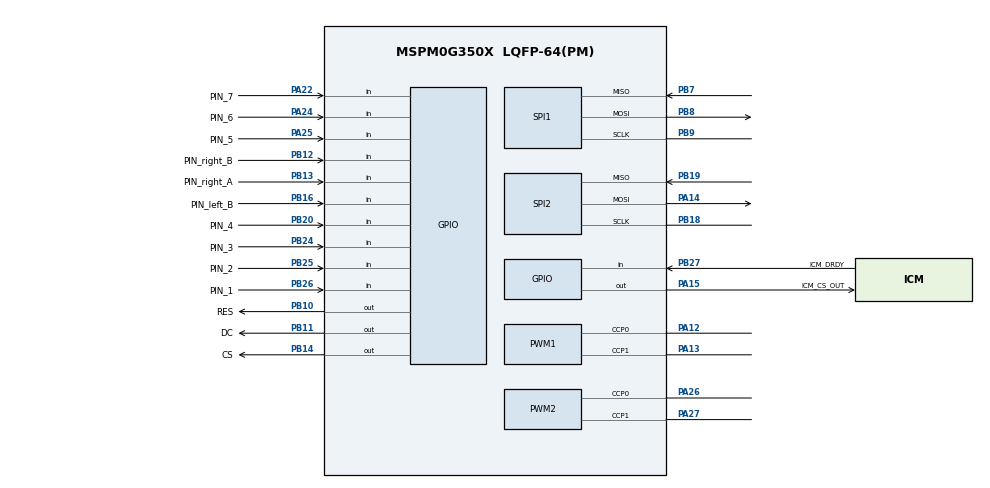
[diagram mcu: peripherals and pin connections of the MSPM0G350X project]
/**
 * @cliArgs --device "MSPM0G350X" --part "Default" --package "LQFP-64(PM)" --product "mspm0_sdk@2.10.00.04"
 * @versions {"tool":"1.26.2+4477"}
 */

/**
 * Import the modules used in this configuration.
 */
const GPIO   = scripting.addModule("/ti/driverlib/GPIO", {}, false);
const GPIO1  = GPIO.addInstance();
const GPIO2  = GPIO.addInstance();
const GPIO3  = GPIO.addInstance();
const GPIO4  = GPIO.addInstance();
const GPIO5  = GPIO.addInstance();
const PWM    = scripting.addModule("/ti/driverlib/PWM", {}, false);
const PWM1   = PWM.addInstance();
const PWM2   = PWM.addInstance();
const SPI    = scripting.addModule("/ti/driverlib/SPI", {}, false);
const SPI1   = SPI.addInstance();
const SPI2   = SPI.addInstance();
const SYSCTL = scripting.addModule("/ti/driverlib/SYSCTL");
const TIMER  = scripting.addModule("/ti/driverlib/TIMER", {}, false);
const TIMER1 = TIMER.addInstance();

/**
 * Write custom configuration values to the imported modules.
 */
const divider9       = system.clockTree["UDIV"];
divider9.divideValue = 2;

const mux4       = system.clockTree["EXHFMUX"];
mux4.inputSelect = "EXHFMUX_XTAL";

const mux8       = system.clockTree["HSCLKMUX"];
mux8.inputSelect = "HSCLKMUX_SYSPLL2X";

const mux12       = system.clockTree["SYSPLLMUX"];
mux12.inputSelect = "zSYSPLLMUX_HFCLK";

const pinFunction4       = system.clockTree["HFXT"];
pinFunction4.enable      = true;
pinFunction4.inputFreq   = 40;
pinFunction4.HFXTStartup = 10;

GPIO1.$name                         = "OLED";
GPIO1.port                          = "PORTB";
GPIO1.associatedPins.create(3);
GPIO1.associatedPins[0].$name       = "RES";
GPIO1.associatedPins[0].ioStructure = "SD";
GPIO1.associatedPins[0].assignedPin = "10";
GPIO1.associatedPins[0].pin.$assign = "PB10";
GPIO1.associatedPins[1].$name       = "DC";
GPIO1.associatedPins[1].ioStructure = "SD";
GPIO1.associatedPins[1].assignedPin = "11";
GPIO1.associatedPins[1].pin.$assign = "PB11";
GPIO1.associatedPins[2].$name       = "CS";
GPIO1.associatedPins[2].ioStructure = "SD";
GPIO1.associatedPins[2].assignedPin = "14";
GPIO1.associatedPins[2].pin.$assign = "PB14";

const Board = scripting.addModule("/ti/driverlib/Board", {}, false);

GPIO2.$name                          = "ICM_CS";
GPIO2.associatedPins[0].$name        = "ICM_CS_OUT";
GPIO2.associatedPins[0].assignedPort = "PORTA";
GPIO2.associatedPins[0].assignedPin  = "15";
GPIO2.associatedPins[0].pin.$assign  = "PA15";

GPIO3.$name                          = "ICM_INT";
GPIO3.associatedPins[0].$name        = "ICM_DRDY";
GPIO3.associatedPins[0].assignedPort = "PORTB";
GPIO3.associatedPins[0].assignedPin  = "27";
GPIO3.associatedPins[0].direction    = "INPUT";
GPIO3.associatedPins[0].interruptEn  = true;
GPIO3.associatedPins[0].polarity     = "RISE";
GPIO3.associatedPins[0].pin.$assign  = "PB27";

GPIO4.$name                              = "GPIO_Encoder";
GPIO4.associatedPins.create(4);
GPIO4.associatedPins[0].$name            = "PIN_right_A";
GPIO4.associatedPins[0].direction        = "INPUT";
GPIO4.associatedPins[0].interruptEn      = true;
GPIO4.associatedPins[0].polarity         = "RISE";
GPIO4.associatedPins[0].internalResistor = "PULL_UP";
GPIO4.associatedPins[0].pin.$assign      = "PB13";
GPIO4.associatedPins[1].$name            = "PIN_right_B";
GPIO4.associatedPins[1].direction        = "INPUT";
GPIO4.associatedPins[1].internalResistor = "PULL_UP";
GPIO4.associatedPins[1].interruptEn      = true;
GPIO4.associatedPins[1].polarity         = "RISE";
GPIO4.associatedPins[1].pin.$assign      = "PB12";
GPIO4.associatedPins[2].direction        = "INPUT";
GPIO4.associatedPins[2].internalResistor = "PULL_UP";
GPIO4.associatedPins[2].interruptEn      = true;
GPIO4.associatedPins[2].polarity         = "RISE";
GPIO4.associatedPins[2].$name            = "PIN_left_A";
GPIO4.associatedPins[3].$name            = "PIN_left_B";
GPIO4.associatedPins[3].direction        = "INPUT";
GPIO4.associatedPins[3].interruptEn      = true;
GPIO4.associatedPins[3].polarity         = "RISE";
GPIO4.associatedPins[3].internalResistor = "PULL_UP";
GPIO4.associatedPins[3].pin.$assign      = "PB16";

GPIO5.$name                              = "GPIO_xunji";
GPIO5.associatedPins.create(7);
GPIO5.associatedPins[0].$name            = "PIN_1";
GPIO5.associatedPins[0].direction        = "INPUT";
GPIO5.associatedPins[0].internalResistor = "PULL_DOWN";
GPIO5.associatedPins[0].pin.$assign      = "PB26";
GPIO5.associatedPins[1].$name            = "PIN_2";
GPIO5.associatedPins[1].direction        = "INPUT";
GPIO5.associatedPins[1].internalResistor = "PULL_DOWN";
GPIO5.associatedPins[1].pin.$assign      = "PB25";
GPIO5.associatedPins[2].$name            = "PIN_3";
GPIO5.associatedPins[2].direction        = "INPUT";
GPIO5.associatedPins[2].internalResistor = "PULL_DOWN";
GPIO5.associatedPins[2].pin.$assign      = "PB24";
GPIO5.associatedPins[3].$name            = "PIN_4";
GPIO5.associatedPins[3].direction        = "INPUT";
GPIO5.associatedPins[3].internalResistor = "PULL_DOWN";
GPIO5.associatedPins[3].pin.$assign      = "PB20";
GPIO5.associatedPins[4].$name            = "PIN_5";
GPIO5.associatedPins[4].direction        = "INPUT";
GPIO5.associatedPins[4].internalResistor = "PULL_DOWN";
GPIO5.associatedPins[4].pin.$assign      = "PA25";
GPIO5.associatedPins[5].$name            = "PIN_6";
GPIO5.associatedPins[5].direction        = "INPUT";
GPIO5.associatedPins[5].internalResistor = "PULL_DOWN";
GPIO5.associatedPins[5].pin.$assign      = "PA24";
GPIO5.associatedPins[6].$name            = "PIN_7";
GPIO5.associatedPins[6].direction        = "INPUT";
GPIO5.associatedPins[6].internalResistor = "PULL_DOWN";
GPIO5.associatedPins[6].pin.$assign      = "PA22";

PWM1.$name                              = "PWM_left";
PWM1.timerStartTimer                    = true;
PWM1.peripheral.ccp0Pin.$assign         = "PA12";
PWM1.peripheral.ccp1Pin.$assign         = "PA13";
PWM1.PWM_CHANNEL_0.$name                = "ti_driverlib_pwm_PWMTimerCC0";
PWM1.PWM_CHANNEL_1.$name                = "ti_driverlib_pwm_PWMTimerCC1";
PWM1.ccp0PinConfig.$name                = "ti_driverlib_gpio_GPIOPinGeneric0";
PWM1.ccp0PinConfig.direction            = scripting.forceWrite("OUTPUT");
PWM1.ccp0PinConfig.hideOutputInversion  = scripting.forceWrite(false);
PWM1.ccp0PinConfig.onlyInternalResistor = scripting.forceWrite(false);
PWM1.ccp0PinConfig.passedPeripheralType = scripting.forceWrite("Digital");
PWM1.ccp1PinConfig.$name                = "ti_driverlib_gpio_GPIOPinGeneric1";
PWM1.ccp1PinConfig.direction            = scripting.forceWrite("OUTPUT");
PWM1.ccp1PinConfig.hideOutputInversion  = scripting.forceWrite(false);
PWM1.ccp1PinConfig.onlyInternalResistor = scripting.forceWrite(false);
PWM1.ccp1PinConfig.passedPeripheralType = scripting.forceWrite("Digital");

PWM2.$name                              = "PWM_right";
PWM2.timerStartTimer                    = true;
PWM2.clockDivider                       = 2;
PWM2.peripheral.ccp0Pin.$assign         = "PA26";
PWM2.peripheral.ccp1Pin.$assign         = "PA27";
PWM2.PWM_CHANNEL_0.$name                = "ti_driverlib_pwm_PWMTimerCC2";
PWM2.PWM_CHANNEL_1.$name                = "ti_driverlib_pwm_PWMTimerCC3";
PWM2.ccp0PinConfig.$name                = "ti_driverlib_gpio_GPIOPinGeneric2";
PWM2.ccp0PinConfig.direction            = scripting.forceWrite("OUTPUT");
PWM2.ccp0PinConfig.hideOutputInversion  = scripting.forceWrite(false);
PWM2.ccp0PinConfig.onlyInternalResistor = scripting.forceWrite(false);
PWM2.ccp0PinConfig.passedPeripheralType = scripting.forceWrite("Digital");
PWM2.ccp1PinConfig.$name                = "ti_driverlib_gpio_GPIOPinGeneric3";
PWM2.ccp1PinConfig.direction            = scripting.forceWrite("OUTPUT");
PWM2.ccp1PinConfig.hideOutputInversion  = scripting.forceWrite(false);
PWM2.ccp1PinConfig.onlyInternalResistor = scripting.forceWrite(false);
PWM2.ccp1PinConfig.passedPeripheralType = scripting.forceWrite("Digital");

SPI1.$name                              = "SPI_OLED";
SPI1.frameFormat                        = "MOTO3";
SPI1.sclkPinConfig.$name                = "ti_driverlib_gpio_GPIOPinGeneric4";
SPI1.sclkPinConfig.direction            = scripting.forceWrite("OUTPUT");
SPI1.sclkPinConfig.onlyInternalResistor = scripting.forceWrite(false);
SPI1.sclkPinConfig.passedPeripheralType = scripting.forceWrite("Digital");
SPI1.mosiPinConfig.$name                = "ti_driverlib_gpio_GPIOPinGeneric5";
SPI1.mosiPinConfig.direction            = scripting.forceWrite("OUTPUT");
SPI1.mosiPinConfig.hideOutputInversion  = scripting.forceWrite(false);
SPI1.mosiPinConfig.onlyInternalResistor = scripting.forceWrite(false);
SPI1.mosiPinConfig.passedPeripheralType = scripting.forceWrite("Digital");
SPI1.misoPinConfig.$name                = "ti_driverlib_gpio_GPIOPinGeneric6";
SPI1.misoPinConfig.onlyInternalResistor = scripting.forceWrite(false);
SPI1.misoPinConfig.passedPeripheralType = scripting.forceWrite("Digital");
SPI1.peripheral.$assign                 = "SPI1";
SPI1.peripheral.sclkPin.$assign         = "PB9";
SPI1.peripheral.mosiPin.$assign         = "PB8";
SPI1.peripheral.misoPin.$assign         = "PB7";

SPI2.$name                              = "SPI_ICM45686";
SPI2.polarity                           = "1";
SPI2.phase                              = "1";
SPI2.targetBitRate                      = 2000000;
SPI2.frameFormat                        = "MOTO3";
SPI2.sclkPinConfig.direction            = scripting.forceWrite("OUTPUT");
SPI2.sclkPinConfig.onlyInternalResistor = scripting.forceWrite(false);
SPI2.sclkPinConfig.passedPeripheralType = scripting.forceWrite("Digital");
SPI2.sclkPinConfig.$name                = "ti_driverlib_gpio_GPIOPinGeneric9";
SPI2.mosiPinConfig.direction            = scripting.forceWrite("OUTPUT");
SPI2.mosiPinConfig.hideOutputInversion  = scripting.forceWrite(false);
SPI2.mosiPinConfig.onlyInternalResistor = scripting.forceWrite(false);
SPI2.mosiPinConfig.passedPeripheralType = scripting.forceWrite("Digital");
SPI2.mosiPinConfig.$name                = "ti_driverlib_gpio_GPIOPinGeneric10";
SPI2.misoPinConfig.onlyInternalResistor = scripting.forceWrite(false);
SPI2.misoPinConfig.passedPeripheralType = scripting.forceWrite("Digital");
SPI2.misoPinConfig.$name                = "ti_driverlib_gpio_GPIOPinGeneric11";
SPI2.peripheral.$assign                 = "SPI0";
SPI2.peripheral.sclkPin.$assign         = "PB18";
SPI2.peripheral.mosiPin.$assign         = "PA14";
SPI2.peripheral.misoPin.$assign         = "PB19";

SYSCTL.forceDefaultClkConfig = true;
SYSCTL.clockTreeEn           = true;

TIMER1.timerStartTimer    = true;
TIMER1.timerMode          = "PERIODIC";
TIMER1.timerPeriod        = "1 ms";
TIMER1.interrupts         = ["ZERO"];
TIMER1.$name              = "TIMER_12";
TIMER1.peripheral.$assign = "TIMG12";

/**
 * Pinmux solution for unlocked pins/peripherals. This ensures that minor changes to the automatic solver in a future
 * version of the tool will not impact the pinmux you originally saw.  These lines can be completely deleted in order to
 * re-solve from scratch.
 */
pinFunction4.peripheral.$suggestSolution           = "SYSCTL";
pinFunction4.peripheral.hfxInPin.$suggestSolution  = "PA5";
pinFunction4.peripheral.hfxOutPin.$suggestSolution = "PA6";
Board.peripheral.$suggestSolution                  = "DEBUGSS";
Board.peripheral.swclkPin.$suggestSolution         = "PA20";
Board.peripheral.swdioPin.$suggestSolution         = "PA19";
GPIO4.associatedPins[2].pin.$suggestSolution       = "PB15";
PWM1.peripheral.$suggestSolution                   = "TIMG0";
PWM2.peripheral.$suggestSolution                   = "TIMG7";
